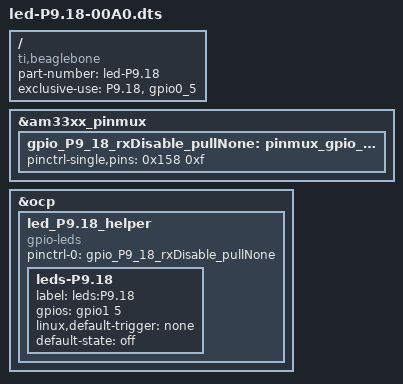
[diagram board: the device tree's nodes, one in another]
/*
* Easy gpio mux control of "P9.18" ("gpio0_5")
*/
/dts-v1/;
/plugin/;

/ {
	compatible = "ti,beaglebone", "ti,beaglebone-black";

	/* identification */
	part-number = "led-P9.18";
	/* version = "00A0"; */

	/* state the resources this cape uses */
	exclusive-use =
		/* the pin header uses */
		"P9.18",

		/* the hardware IP uses */
		"gpio0_5";
	
	
	/* rxDisable_pullNone state */
	fragment@0 {
		target = <&am33xx_pinmux>;
		__overlay__ {
			gpio_P9_18_rxDisable_pullNone: pinmux_gpio_P9.18_rxDisable_pullNone {
				pinctrl-single,pins = <
					0x158 0xf
				>;
			};
		};
	};

	fragment@1 {
		target = <&ocp>;
		__overlay__ {
			led_P9.18_helper {
				compatible = "gpio-leds";
				pinctrl-names = "default";
				pinctrl-0 = <&gpio_P9_18_rxDisable_pullNone>;
				
				leds-P9.18 {
					label = "leds:P9.18";
					gpios = <&gpio1 5 0>;
					linux,default-trigger = "none";
					default-state = "off";
				};
			};
			
		};
	};

};
